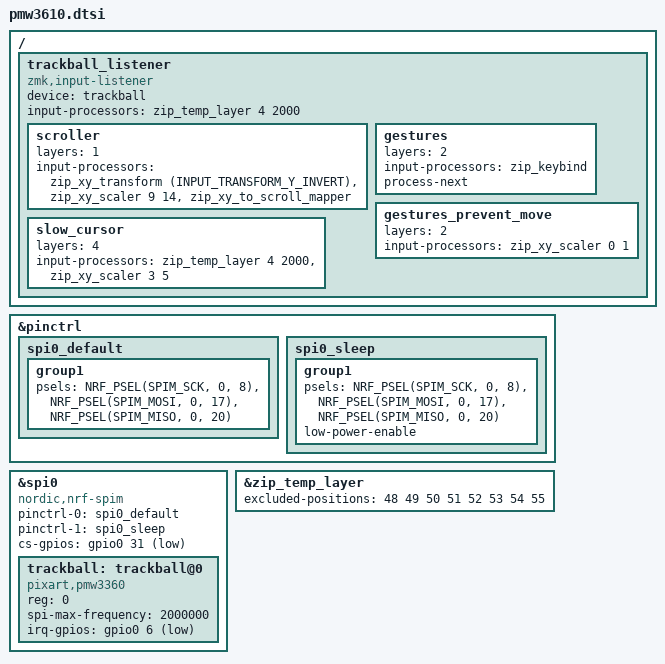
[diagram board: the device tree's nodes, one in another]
#include <input/processors.dtsi>
#include <dt-bindings/zmk/input_transform.h>

&pinctrl {
    spi0_default: spi0_default {
        group1 {
            psels = <NRF_PSEL(SPIM_SCK, 0, 8)>,
                <NRF_PSEL(SPIM_MOSI, 0, 17)>,
                <NRF_PSEL(SPIM_MISO, 0, 20)>;
        };
    };

    spi0_sleep: spi0_sleep {
        group1 {
            psels = <NRF_PSEL(SPIM_SCK, 0, 8)>,
                <NRF_PSEL(SPIM_MOSI, 0, 17)>,
                <NRF_PSEL(SPIM_MISO, 0, 20)>;
            low-power-enable;
        };
    };
};

&spi0 {
    status = "okay";
    compatible = "nordic,nrf-spim";
    pinctrl-0 = <&spi0_default>;
    pinctrl-1 = <&spi0_sleep>;
    pinctrl-names = "default", "sleep";
    cs-gpios = <&gpio0 31 GPIO_ACTIVE_LOW>;

    trackball: trackball@0 {
        status = "okay";
        compatible = "pixart,pmw3360";
        reg = <0>;
        spi-max-frequency = <2000000>;
        irq-gpios = <&gpio0 6 (GPIO_ACTIVE_LOW | GPIO_PULL_UP)>;

        /*   optional features   */
        // snipe-layers = <1>;
        // scroll-layers = <2 3>;
        // automouse-layer = <4>;
    };
};

// Auto-mouse layer (4) deactivation: by default ANY keypress drops the temp
// layer. Exclude all thumb positions (48-55) so the mouse buttons, LOWER and
// RAISE never drop it -- only the main (non-thumb) keys deactivate the layer.
&zip_temp_layer {
    excluded-positions = <48 49 50 51 52 53 54 55>;
};

/ {
  trackball_listener {
    compatible = "zmk,input-listener";
    device = <&trackball>;

    // Activate the MOUSE layer (index 4) for 2000ms on trackball movement.
    input-processors = <&zip_temp_layer 4 2000>;

    // On the LOWER layer (index 1), trackball movement scrolls instead of moving the cursor.
    // Y is inverted so vertical scroll feels natural (left/right is already correct).
    // zip_xy_scaler 9/14 slows scroll to ~65% (9/14 = 0.643; exact 0.65 = 13/20 exceeds the 16 cap).
    scroller {
        layers = <1>;
        input-processors = <&zip_xy_transform (INPUT_TRANSFORM_Y_INVERT)>, <&zip_xy_scaler 9 14>, <&zip_xy_to_scroll_mapper>;
    };

    // On the RAISE layer (index 2), movement is quantized into keystrokes:
    // left/right switch virtual desktops, up/down are volume (see &zip_keybind in the keymap).
    // `process-next` lets the next override run so we can cancel the raw motion below.
    // (ZMK still reports default movement for layer-overrides; see zmkfirmware/zmk#2967.)
    gestures {
        layers = <2>;
        input-processors = <&zip_keybind>;
        process-next;
    };

    // Zero the trackball motion on RAISE so the cursor doesn't drift while gesturing.
    gestures_prevent_move {
        layers = <2>;
        input-processors = <&zip_xy_scaler 0 1>;
    };

    // Slow plain cursor movement to 60% (x3/5). Targets the auto MOUSE layer (4),
    // which is active during normal pointing. Placed last so the scroller (LOWER)
    // and gesture (RAISE) overrides above match first and stop the chain -> this
    // never runs while scrolling or gesturing, leaving those speeds untouched.
    //
    // zip_temp_layer is repeated here because a layer-override REPLACES the listener's
    // default processors (it does not run in addition to them). Without it, once layer 4
    // is active this override takes over and the default `&zip_temp_layer 4 2000` no
    // longer runs, so continued movement never refreshes the timeout -> the layer expires
    // a fixed 2s after the FIRST move and drops mid-use (stray BASE thumb -> Start menu).
    // Re-arming it here turns the timeout into a true sliding window: it only expires
    // after 2s of real idle. Keep this value in sync with the default above.
    slow_cursor {
        layers = <4>;
        input-processors = <&zip_temp_layer 4 2000>, <&zip_xy_scaler 3 5>;
    };
  };
};
